# MU3E_FULL8LANE_TYPE0_SYSTEM_SC_HUB register map
Vendor: Mu3e; Series: MU3E_FULL8LANE_TYPE0; File version: 2026.05.06
Registers are 32-bit, read-write, reset 0x0 unless marked. A register's access mark holds for its fields unless they carry their own. Offsets are from the block's base; [hi:lo] are bit positions; {n}, {i} and the like mark numbered series.

## DATA_PATH_SUBSYSTEM_HIT_STACK_SUBSYSTEM_0_RING_BUFFER_CAM_0_CSR — Datapath-local slave expanded below the SC-hub mm_bridge.s0 aperture. Qsys slave data_path_subsystem_hit_stack_subsystem_0_ring_buffer_cam_0.csr is SC-hub-relative at 0x0002B000 with compiled aperture size 0x00000080. Compiled Qsys module version was not found in the source .qsys files. No source SVD file was present; this peripheral is generated as an explicitly raw window. Hit-stack ring-buffer CAM CSR window; no local system-matching SVD source was present in this worktree.
Base 0x0002B000
{0x0+4i} RAW_WORD_{i:02} (i=0..31) — Undecoded raw 32-bit word {i} in data_path_subsystem_hit_stack_subsystem_0_ring_buffer_cam_0.csr. The compiled Qsys map exposes this word, but no semantic source SVD was present.
  [31:0] value — Raw 32-bit value for word {i}.

## DATA_PATH_SUBSYSTEM_HIT_STACK_SUBSYSTEM_0_RING_BUFFER_CAM_1_CSR — Datapath-local slave expanded below the SC-hub mm_bridge.s0 aperture. Qsys slave data_path_subsystem_hit_stack_subsystem_0_ring_buffer_cam_1.csr is SC-hub-relative at 0x0002B080 with compiled aperture size 0x00000080. Compiled Qsys module version was not found in the source .qsys files. No source SVD file was present; this peripheral is generated as an explicitly raw window. Hit-stack ring-buffer CAM CSR window; no local system-matching SVD source was present in this worktree.
Base 0x0002B080
{0x0+4i} RAW_WORD_{i:02} (i=0..31) — Undecoded raw 32-bit word {i} in data_path_subsystem_hit_stack_subsystem_0_ring_buffer_cam_1.csr. The compiled Qsys map exposes this word, but no semantic source SVD was present.
  [31:0] value — Raw 32-bit value for word {i}.

## DATA_PATH_SUBSYSTEM_HIT_STACK_SUBSYSTEM_0_RING_BUFFER_CAM_2_CSR — Datapath-local slave expanded below the SC-hub mm_bridge.s0 aperture. Qsys slave data_path_subsystem_hit_stack_subsystem_0_ring_buffer_cam_2.csr is SC-hub-relative at 0x0002B100 with compiled aperture size 0x00000080. Compiled Qsys module version was not found in the source .qsys files. No source SVD file was present; this peripheral is generated as an explicitly raw window. Hit-stack ring-buffer CAM CSR window; no local system-matching SVD source was present in this worktree.
Base 0x0002B100
{0x0+4i} RAW_WORD_{i:02} (i=0..31) — Undecoded raw 32-bit word {i} in data_path_subsystem_hit_stack_subsystem_0_ring_buffer_cam_2.csr. The compiled Qsys map exposes this word, but no semantic source SVD was present.
  [31:0] value — Raw 32-bit value for word {i}.

## DATA_PATH_SUBSYSTEM_HIT_STACK_SUBSYSTEM_0_RING_BUFFER_CAM_3_CSR — Datapath-local slave expanded below the SC-hub mm_bridge.s0 aperture. Qsys slave data_path_subsystem_hit_stack_subsystem_0_ring_buffer_cam_3.csr is SC-hub-relative at 0x0002B180 with compiled aperture size 0x00000080. Compiled Qsys module version was not found in the source .qsys files. No source SVD file was present; this peripheral is generated as an explicitly raw window. Hit-stack ring-buffer CAM CSR window; no local system-matching SVD source was present in this worktree.
Base 0x0002B180
{0x0+4i} RAW_WORD_{i:02} (i=0..31) — Undecoded raw 32-bit word {i} in data_path_subsystem_hit_stack_subsystem_0_ring_buffer_cam_3.csr. The compiled Qsys map exposes this word, but no semantic source SVD was present.
  [31:0] value — Raw 32-bit value for word {i}.

## DATA_PATH_SUBSYSTEM_MUTRIG_INJECTOR_0_CSR — Datapath-local slave expanded below the SC-hub mm_bridge.s0 aperture. Qsys slave data_path_subsystem_mutrig_injector_0.csr is SC-hub-relative at 0x0002B200 with compiled aperture size 0x00000040. Compiled Qsys module mutrig_injector_0 kind=mutrig_injector_multiheader version=26.0.3.429 from full8lane_type0_datapath.qsys. Version/identity parameters: VERSION_MAJOR=26, VERSION_MINOR=0, VERSION_PATCH=3, BUILD=429, VERSION_DATE=20260429, VERSION_GIT=1385020117, IP_UID=1296649802, INSTANCE_ID=0. Source SVD charge_injection/script/mutrig_injector.svd version 26.0.3.0429. Relative 16-word control/status aperture for the MuTRiG injector.
Base 0x0002B200
0x00 UID ro reset 0x4D494E4A — Software-visible IP identifier. Default payload is ASCII MINJ.
  [31:0] uid — Compile-time / integration-time IP identifier.
0x04 META reset 0x1A0031AD — Read-multiplexed metadata word. Write 0=VERSION, 1=VERSION_DATE, 2=VERSION_GIT, 3=INSTANCE_ID before reading back.
  [1:0] page_select — Write selector: 0=VERSION, 1=VERSION_DATE, 2=VERSION_GIT, 3=INSTANCE_ID.
  [31:0] meta_payload ro — Read payload for the selected metadata page. VERSION packs MAJOR[31:24], MINOR[23:16], PATCH[15:12], BUILD[11:0].
0x08 MODE — Injection mode selector. Writing value 4 emits a one-click pulse and stores mode 0. Writing value 5 also reseeds PRBS state.
  [3:0] mode — 0=off/one-click return, 1=header synchronous, 2=periodic main clock, 3=periodic oscillator clock, 4=one-click command, 5=PRBS random.
0x0C HEADER_DELAY reset 0x64 — Main-clock delay from selected header match to first header-synchronous pulse.
  [31:0] cycles — Header delay in clock_interface cycles.
0x10 HEADER_INTERVAL reset 0x1 — Number of selected header matches between mode-1 bursts.
  [31:0] matches — Selected-header match interval.
0x14 INJECTION_MULTIPLICITY reset 0x1 — Number of pulses in each header-triggered or PRBS-triggered burst.
  [31:0] count — Pulse count per burst.
0x18 HEADER_CH — Selected header channel. The RTL compares this value against all eight headerinfo channel sidebands.
  [7:0] channel — Selected header channel. Width is set by HEADERINFO_CHANNEL_W in Platform Designer.
0x1C PULSE_INTERVAL reset 0x3E8 — Mode-2 interval in main-clock cycles. Mode 3 derives the oscillator-domain interval from this value.
  [31:0] cycles — Pulse period before mode-3 clock-domain scaling. Use 1250 for 100 kHz at 125 MHz.
0x20 PULSE_HIGH_CYCLES reset 0x5 — Pulse high duration. RTL uses bits [7:0] and enforces a minimum low gap between burst pulses.
  [7:0] cycles — Pulse high duration in cycles.
0x24 PRBS_RATE reset 0x3E7 — Number of main-clock cycles between PRBS state advances in mode 5.
  [31:0] cycles — PRBS advance interval.
0x28 PRBS_PATTERN reset 0x1 — Pattern compared against the low PRBS bits selected by PRBS_CTRL.
  [31:0] pattern — Pattern bits used for PRBS match.
0x2C PRBS_SEED reset 0xACE1 — Seed used when entering or reseeding mode 5. All-zero selected bits are sanitized to bit 0 set.
  [31:0] seed — PRBS seed word.
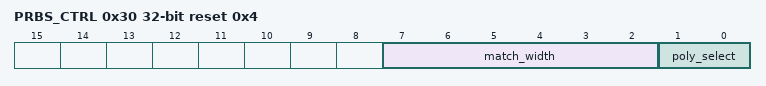
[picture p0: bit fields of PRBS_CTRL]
0x30 PRBS_CTRL reset 0x4 — PRBS polynomial and match-width selector.
  [7:2] match_width — Number of low PRBS bits compared against PRBS_PATTERN, clipped to selected polynomial width. Zero is treated as one.
  [1:0] poly_select — 0=PRBS7, 1=PRBS15, 2=PRBS23, 3=PRBS31.
{0x0+4i} RESERVED{i} ro (i=13..15) — Reserved decoded word. Current RTL returns zero and ignores writes.
  [31:0] value — Reserved zero readback.
